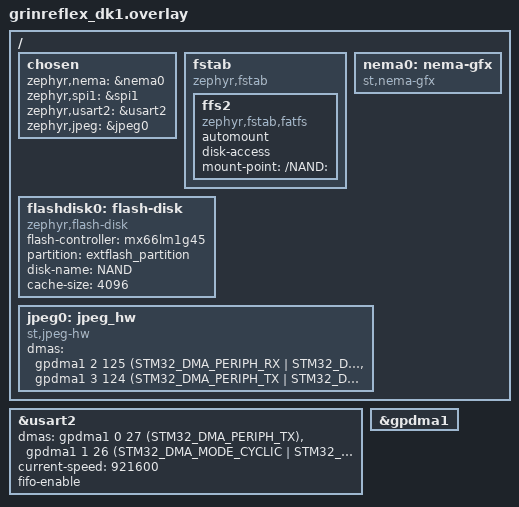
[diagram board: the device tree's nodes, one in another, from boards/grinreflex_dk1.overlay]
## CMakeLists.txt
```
#-------------------------------------------------------------------------------
# Zephyr Example Application
#
# Copyright (c) 2021 Nordic Semiconductor ASA
# SPDX-License-Identifier: Apache-2.0

cmake_minimum_required(VERSION 3.13.1)

set(EXTRA_CONF_FILE
    ${CMAKE_CURRENT_SOURCE_DIR}/lvgl.conf;
)

find_package(Zephyr REQUIRED HINTS $ENV{ZEPHYR_BASE})

project(app)

# TODO: below two lines are unclear
set(NO_THREADSAFE_STATICS $<TARGET_PROPERTY:compiler-cpp,no_threadsafe_statics>)
zephyr_compile_options($<$<COMPILE_LANGUAGE:CXX>:${NO_THREADSAFE_STATICS}>)

if (CONFIG_OPENCV_LIB)
    include(opencv.cmake)
endif()

if (CONFIG_NEMA)
    include(nema.cmake)
endif()

target_include_directories(app PRIVATE
    src
)

target_sources(app PRIVATE
    src/main.c
    src/gfx_utils.cpp
    src/video.cpp
)

if (CONFIG_BOARD_GRINREFLEX_DK1)
target_sources(app PRIVATE
    src/sample_usbd_init.c
    src/lvgl_fs_sample.c
    src/uart.cpp
    src/grinreflex.cpp
)
endif()

if (CONFIG_BOARD_GRINREFLEX_DK2)
target_sources(app PRIVATE
    src/grinreflex_v2.cpp
)
endif()
```

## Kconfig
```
# Copyright (c) 2021 Nordic Semiconductor ASA
# SPDX-License-Identifier: Apache-2.0
#
# This file is the application Kconfig entry point. All application Kconfig
# options can be defined here or included via other application Kconfig files.
# You can browse these options using the west targets menuconfig (terminal) or
# guiconfig (GUI).

#menu "Zephyr"
#source "Kconfig.zephyr"
#endmenu

module = grinreflex
module-str = grinreflex

source "subsys/logging/Kconfig.template.log_config"
source "Kconfig.zephyr"
rsource "Kconfig.sample_usbd"
rsource "Kconfig.sample_msc"
```

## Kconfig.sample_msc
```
menu "MSC sample options"

choice
	prompt "Storage and file system type used by the application"
	default APP_MSC_STORAGE_FLASH_FATFS
	help
	  Specify the type of storage and file system.

config APP_MSC_STORAGE_FLASH_FATFS
	bool "Use FLASH disk and FAT file system"
	imply DISK_DRIVERS
    imply DISK_ACCESS
	imply FILE_SYSTEM
	imply FAT_FILESYSTEM_ELM
    imply FILE_SYSTEM_MKFS
    imply FS_FATFS_FSTAB_AUTOMOUNT

endchoice

config MASS_STORAGE_DISK_NAME
	default "NAND" if DISK_DRIVER_FLASH

if DISK_DRIVER_FLASH

config FLASH_MAP
	default y

config FLASH_PAGE_LAYOUT
	default y

config FLASH_LOG_LEVEL
	default 3

endif # DISK_DRIVER_FLASH

endmenu
```

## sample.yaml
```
# This file is provided so that the application can be compiled using Twister,
# the Zephyr testing tool. In this file, multiple combinations can be specified,
# so that you can easily test all of them locally or in CI.
sample:
  description: Example application
  name: example-application 
common:
  build_only: true
  integration_platforms:
    - custom_plank
    - nucleo_f302r8
    - grinreflex-dk1

  modules:
    - lvgl
    - tflite-micro
```

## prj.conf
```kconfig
# Copyright (c) 2021 Nordic Semiconductor ASA
# SPDX-License-Identifier: Apache-2.0
#
# This is a Kconfig fragment which can be used to enable debug-related options
# in the application. See the README for more details.

CONFIG_CPP=y
CONFIG_STD_CPP20=y

CONFIG_MAIN_STACK_SIZE=65536

CONFIG_DISPLAY=y
CONFIG_DISPLAY_LOG_LEVEL_ERR=y

CONFIG_LOG=y
CONFIG_LOG_DEFAULT_LEVEL=3
CONFIG_SHELL=y

CONFIG_INPUT=y

CONFIG_LOG=y
CONFIG_LOG_MODE_MINIMAL=y
CONFIG_USB_DEVICE_INITIALIZE_AT_BOOT=n

CONFIG_REQUIRES_FULL_LIBC=y
CONFIG_GLIBCXX_LIBCPP=y

CONFIG_NEWLIB_LIBC=y
CONFIG_PICOLIBC=n

CONFIG_POSIX_API=y

CONFIG_ASSERT=y
CONFIG_STACK_SENTINEL=y
CONFIG_THREAD_STACK_INFO=y
CONFIG_INIT_STACKS=y           # fill stacks, helps detect overflow
CONFIG_LOG=y
CONFIG_LOG_MODE_DEFERRED=n     # immediate logs
CONFIG_DEBUG_OPTIMIZATIONS=y

CONFIG_COMMON_LIBC_MALLOC=y
CONFIG_HEAP_MEM_POOL_SIZE=49152
CONFIG_COMMON_LIBC_MALLOC_ARENA_SIZE=2228224
#CONFIG_COMMON_LIBC_MALLOC_ARENA_SIZE=1048576


#CONFIG_TFLITE_LIB=y
CONFIG_OPENCV_LIB=y
#CONFIG_QUIRC_LIB=y
CONFIG_NEMA=y

CONFIG_FPU=y
CONFIG_FP_SOFTABI=y

CONFIG_GPIO=y
#CONFIG_SPI=y
#CONFIG_SPI_LOG_LEVEL_DBG=y

CONFIG_DMA=y
CONFIG_SERIAL=y
CONFIG_UART_ASYNC_API=y
CONFIG_RING_BUFFER=y
#CONFIG_UART_LOG_LEVEL_DBG=y


CONFIG_UART_INTERRUPT_DRIVEN=y

CONFIG_STM32_JPEG=y

CONFIG_CPP_EXCEPTIONS=y
CONFIG_CPP_RTTI=y

#CONFIG_DISPLAY_LOG_LEVEL_DBG=y

CONFIG_DMA_LOG_LEVEL_INF=y
CONFIG_VIDEO_LOG_LEVEL_INF=y

CONFIG_STM32_JPEG_RGB_FORMAT=3
CONFIG_GRINREFLEX_JPEG_VIDEO=y
CONFIG_GRINREFLEX_JPEG_VIDEO_QUALITY=50
CONFIG_GRINREFLEX_VIDEO_WIDTH=320
CONFIG_GRINREFLEX_VIDEO_HEIGHT=240


CONFIG_HW_STACK_PROTECTION=y


# Make asserts print file:line and message
CONFIG_ASSERT=y
CONFIG_ASSERT_VERBOSE=y

# Ensure logs/printk come out before the crash
CONFIG_PRINTK=y
CONFIG_LOG=y
CONFIG_LOG_PRINTK=y
CONFIG_LOG_MODE_IMMEDIATE=y

# Better symbols for gdb
#CONFIG_DEBUG_INFO=y
# (Optional) minimal optimizations for nicer backtraces
CONFIG_NO_OPTIMIZATIONS=y

# Richer fault dump on ARM (registers, etc.)
CONFIG_FAULT_DUMP=2
```

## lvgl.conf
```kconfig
CONFIG_LV_Z_MEM_POOL_SIZE=16384
CONFIG_LV_Z_SHELL=n

CONFIG_LVGL=y
CONFIG_LV_USE_LOG=y
CONFIG_LV_USE_LABEL=y
CONFIG_LV_USE_ARC=y
CONFIG_LV_USE_IMAGE=y
#CONFIG_LV_USE_MONKEY=y
CONFIG_LV_FONT_MONTSERRAT_14=y
#CONFIG_LV_Z_POINTER_INPUT=y

CONFIG_LV_CACHE_DEF_SIZE=4096
CONFIG_LV_IMAGE_HEADER_CACHE_DEF_CNT=1
#CONFIG_LV_USE_TJPGD=y
#CONFIG_LV_USE_FS_MEMFS=y
#CONFIG_LV_USE_FS=y
CONFIG_LV_USE_BUILTIN_MALLOC=n

#CONFIG_LV_USE_PERF_MONITOR=y
#CONFIG_LV_USE_DROPDOWN=y
#CONFIG_LV_USE_SYSMON=y
```

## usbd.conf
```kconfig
CONFIG_USB_DEVICE_STACK_NEXT=y
CONFIG_USBD_MSC_CLASS=y
CONFIG_USBD_MSC_LUNS_PER_INSTANCE=3
CONFIG_USBD_LOG_LEVEL_WRN=y
CONFIG_UDC_DRIVER_LOG_LEVEL_WRN=y

CONFIG_SAMPLE_USBD_PID=0x0008
CONFIG_SAMPLE_USBD_PRODUCT="USBD MSC sample"
```

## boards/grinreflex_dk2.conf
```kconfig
CONFIG_FAT_FILESYSTEM_ELM=n
CONFIG_POSIX_FILE_SYSTEM=n
```

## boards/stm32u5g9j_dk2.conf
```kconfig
CONFIG_USB_DEVICE_STACK_NEXT=y
CONFIG_USBD_MSC_CLASS=y
CONFIG_USBD_MSC_LUNS_PER_INSTANCE=3
CONFIG_USBD_LOG_LEVEL_WRN=y
CONFIG_UDC_DRIVER_LOG_LEVEL_WRN=y

CONFIG_SAMPLE_USBD_PID=0x0008
CONFIG_SAMPLE_USBD_PRODUCT="USBD MSC sample"

CONFIG_FILE_SYSTEM_SHELL=y
```

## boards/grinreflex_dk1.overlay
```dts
/*
 * Copyright (c) 2024, Eve Redero
 *
 * SPDX-License-Identifier: Apache-2.0
 */

#include <zephyr/dt-bindings/input/input-event-codes.h>
#include <zephyr/dt-bindings/lvgl/lvgl.h>

/ {
	chosen: chosen {
		zephyr,nema = &nema0;
		zephyr,spi1 = &spi1;
		zephyr,usart2 = &usart2;
		zephyr,jpeg = &jpeg0;
	};

	fstab {
		compatible = "zephyr,fstab";

        ffs2: ffs2 {
			compatible = "zephyr,fstab,fatfs";
			automount;
			disk-access;
			mount-point = "/NAND:";
		};
	};

    flashdisk0: flash-disk {
        compatible = "zephyr,flash-disk";
        flash-controller = <&mx66lm1g45>;
        partition = <&extflash_partition>;
        disk-name = "NAND";
        cache-size = <4096>;
    };

	nema0: nema-gfx {
		compatible = "st,nema-gfx";
		status = "okay";
	};

	jpeg0: jpeg_hw {
		compatible = "st,jpeg-hw";
		dmas = <&gpdma1 2 125 (STM32_DMA_PERIPH_RX | STM32_DMA_PERIPH_32BITS | STM32_DMA_MEM_32BITS)
				&gpdma1 3 124 (STM32_DMA_PERIPH_TX | STM32_DMA_PERIPH_32BITS | STM32_DMA_MEM_32BITS)>;
		dma-names = "tx", "rx";
		status = "okay";
	};
};

&usart2 {
	dmas = <&gpdma1 0 27 (STM32_DMA_PERIPH_TX)
			&gpdma1 1 26 (STM32_DMA_MODE_CYCLIC | STM32_DMA_PERIPH_RX | STM32_DMA_MEM_8BITS)>;
	dma-names = "tx", "rx";
	current-speed = <921600>;
	fifo-enable;
};

&gpdma1 {
	status = "okay";
};
```

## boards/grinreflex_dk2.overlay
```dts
/*
 * Copyright (c) 2024, Eve Redero
 *
 * SPDX-License-Identifier: Apache-2.0
 */

#include <zephyr/dt-bindings/input/input-event-codes.h>
#include <zephyr/dt-bindings/lvgl/lvgl.h>

/ {
	chosen: chosen {
		zephyr,nema = &nema0;
		zephyr,spi1 = &spi1;
		zephyr,jpeg = &jpeg0;
	};

	nema0: nema-gfx {
		compatible = "st,nema-gfx";
		status = "okay";
	};

	jpeg0: jpeg_hw {
		compatible = "st,jpeg-hw";
		dmas = <&gpdma1 2 125 (STM32_DMA_PERIPH_RX | STM32_DMA_PERIPH_32BITS | STM32_DMA_MEM_32BITS)
				&gpdma1 3 124 (STM32_DMA_PERIPH_TX | STM32_DMA_PERIPH_32BITS | STM32_DMA_MEM_32BITS)>;
		dma-names = "tx", "rx";
		status = "okay";
	};
};

&gpdma1 {
	status = "okay";
};

&dcmi {
	jpeg-dev = <&jpeg0>;
};
```

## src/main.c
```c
/*
 * Copyright (c) 2024 Charles Dias <charlesdias.cd@outlook.com>
 *
 * SPDX-License-Identifier: Apache-2.0
 */

#include <zephyr/kernel.h>
#include <zephyr/device.h>
#include <zephyr/drivers/display.h>
#include <zephyr/drivers/video.h>
#include <zephyr/drivers/video-controls.h>
#include <zephyr/logging/log.h>
#include <lvgl.h>

#define CONFIG_VIDEO_WIDTH 160
#define CONFIG_VIDEO_HEIGHT 120

#include "grinreflex.h"

LOG_MODULE_REGISTER(main, CONFIG_LOG_DEFAULT_LEVEL);

#if !DT_HAS_CHOSEN(zephyr_camera)
#error No camera chosen in devicetree. Missing "--shield" or "--snippet video-sw-generator" flag?
#endif

#if !DT_HAS_CHOSEN(zephyr_display)
#error No display chosen in devicetree. Missing "--shield" flag?
#endif

int main(void)
{
	init();

	while (1)
	{
		loop();
	}
}
```

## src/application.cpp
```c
#include <iostream>

#include "lvgl.h"

#include "gfx_utils.hpp"
#if defined(CONFIG_OPENCV_LIB)
#include "opencv_utils.hpp"
#endif

#include "uart.hpp"
#include <app/drivers/jpeg.h>

#include "application.h"

#define JPEG_DEVICE_NODE DT_CHOSEN(zephyr_jpeg)

#define NAND_PATH(_path) ("/NAND:" _path)

#if defined(CONFIG_OPENCV_LIB)
static cv::CascadeClassifier faceCascade;
#endif

#define UART_RING_BUF_SIZE 8192
static uint8_t uart_ring_buf[UART_RING_BUF_SIZE];

static lv_obj_t *canvas;
static lv_obj_t *jpeg_img;

UartEx uartEx = UartEx(uart_ring_buf, sizeof(uart_ring_buf));

const struct device *jpeg_dev = DEVICE_DT_GET(JPEG_DEVICE_NODE);

int init() {

#if defined(CONFIG_OPENCV_LIB)
  const char *faceCascadePath = NAND_PATH("/alt.xml");

  cv::setNumThreads(1);

  uint32_t start_ms = k_uptime_get_32();

  if (!faceCascade.load(faceCascadePath)) {
    std::cerr << "Cannot load cascade: " << faceCascadePath << "\n";
    return -3;
  }

  uint32_t end_ms = k_uptime_get_32();
  uint32_t elapsed = end_ms - start_ms;

  std::cout << "faceCascade.load : " << elapsed << std::endl;

  canvas = lv_canvas_create(lv_screen_active());
  lv_canvas_fill_bg(canvas, lv_color_hex3(0xccc), LV_OPA_COVER);
  lv_obj_center(canvas);

  jpeg_img = lv_img_create(lv_screen_active());

  uartEx.init();
  uartEx.trigger();

  if (!device_is_ready(jpeg_dev)) {
    printf("%s JPEG device not ready", jpeg_dev->name);
    return -ENODEV;
  }
#endif

  return 0;
}

#define TMP_BUF_WIDTH 400
#define TMP_BUF_HEIGHT 400

static uint8_t tmp_buf[TMP_BUF_WIDTH * TMP_BUF_HEIGHT];

int loop() {
#if defined(CONFIG_OPENCV_LIB)
  uint32_t jpeg_buf_len = uartEx.tryReadHeader();

  if (0 == jpeg_buf_len) {
    return 0;
  }

  // memset(tmp_buf, 0, sizeof(tmp_buf));

  static uint8_t uart_buf[8192];
  static uint8_t yuyv_buf[80 * 80 * 3];
  static uint8_t rgb_buf[80 * 80 * 3];
  struct jpeg_out_prop jpeg_prop;

  jpeg_buf_len = uartEx.tryRead(uart_buf, jpeg_buf_len);

  uartEx.trigger();

  jpeg_buf_len = ROUND_UP(jpeg_buf_len, 4);

  jpeg_hw_decode(jpeg_dev, uart_buf, jpeg_buf_len, yuyv_buf);

  jpeg_hw_poll(jpeg_dev, 0, &jpeg_prop);

  printf("JPEG done w = %d, h = %d, color = %d chroma = %d\n", jpeg_prop.width,
         jpeg_prop.height, jpeg_prop.color_space, jpeg_prop.chroma);

  jpeg_color_convert_helper(jpeg_dev, &jpeg_prop, yuyv_buf, rgb_buf);

  // memset(rgb_buf, 0xff, sizeof(rgb_buf));
  uint32_t rgb_size = 80 * 80 * 3;

  cv::Mat mat_rgb(jpeg_prop.height, jpeg_prop.width, CV_8UC3, rgb_buf);
  cv::Mat mat_gray;

  cv::cvtColor(mat_rgb, mat_gray, cv::COLOR_RGB2GRAY);

  const cv::Size minSize(20, 20);
  const cv::Size maxSize(mat_gray.cols, mat_gray.rows);
  const double scaleFactor = 1.3;
  const int minNeighbors = 3;
  const int flags = 0;

  std::vector<cv::Rect> faces;

  uint32_t start_ms = k_uptime_get_32();

  faceCascade.detectMultiScale(mat_gray, faces, scaleFactor, minNeighbors,
                               flags, minSize, maxSize);

  uint32_t end_ms = k_uptime_get_32();
  uint32_t elapsed = end_ms - start_ms;

  printf("detectMultiScale : %d ms\n", elapsed);

  for (const auto &r : faces) {
    cv::rectangle(mat_gray, r, cv::Scalar(255, 255, 255), 2, cv::LINE_8);
    std::cout << "detectMultiScale : " << elapsed << std::endl;
    printf("faces = %d, %d %d\n", faces.size(), mat_gray.cols, mat_gray.rows);
  }

  static Gfx::GfxBuffer src;
  static Gfx::GfxBuffer dst;

  src.buf = mat_gray.data;
  src.width = mat_gray.cols;
  src.height = mat_gray.rows;
  src.stride = mat_gray.cols;
  src.cf = LV_COLOR_FORMAT_L8;
  src.size = mat_gray.rows * mat_gray.cols;

  dst.buf = tmp_buf;
  dst.width = TMP_BUF_WIDTH;
  dst.height = TMP_BUF_HEIGHT;
  dst.stride = TMP_BUF_WIDTH;
  dst.size = sizeof(tmp_buf);
  dst.cf = LV_COLOR_FORMAT_L8;

  Gfx::fit(canvas, src, dst);
#endif
  return 0;
}

/////////////////// Examples /////////////////////////

#if 0

TFLite:

#define IMG_WIDTH 96
#define IMG_HEIGHT 96
#define IMG_BPP 3
#define IMG_SIZE (IMG_WIDTH * IMG_HEIGHT * IMG_BPP)

  static uint8_t img_buf[IMG_SIZE];

  static uint8_t edges_buf[IMG_SIZE / IMG_BPP];

  if (lvgl_fs_load_raw("/NAND:/test.bin", img_buf, IMG_SIZE)) {

    static lv_img_dsc_t img_dsc;
    img_dsc.header.w = IMG_WIDTH;
    img_dsc.header.h = IMG_HEIGHT;
    img_dsc.header.cf = LV_COLOR_FORMAT_A8; //
    img_dsc.data_size = IMG_SIZE / IMG_BPP;
    img_dsc.data = edges_buf;

    lv_obj_t *img = lv_img_create(lv_screen_active());

#if defined(CONFIG_TFLITE_LIB)
    tflm_init();
    inference_task(img_buf);
#endif

    lv_img_set_src(img, &img_dsc);
    lv_obj_center(img);
  }

Edges

#define IMG_WIDTH 320
#define IMG_HEIGHT 240
#define IMG_BPP 3
#define IMG_SIZE (IMG_WIDTH * IMG_HEIGHT * IMG_BPP)

	static uint8_t edges_buf[IMG_SIZE/IMG_BPP];

	uint32_t start_ms = k_uptime_get_32();
	//edge_detect(image_data(), edges_buf, IMG_WIDTH, IMG_HEIGHT, 50.0, 150.0);

	int width, height;
	if (0 == edge_demo("/NAND:/sample2.png", edges_buf, &width, &height, 50.0, 150.0))
	{

		uint32_t end_ms = k_uptime_get_32();
		uint32_t elapsed = end_ms - start_ms;

		printf("Routine took %u ms\n", elapsed);

		static lv_img_dsc_t img_dsc;
		img_dsc.header.w = IMG_WIDTH;
		img_dsc.header.h = IMG_HEIGHT;
		img_dsc.header.cf = LV_COLOR_FORMAT_A8; //
		img_dsc.data_size = IMG_SIZE/IMG_BPP;
		img_dsc.data = edges_buf;

		lv_obj_t *img = lv_img_create(lv_screen_active());

		lv_img_set_src(img, &img_dsc);
		lv_obj_center(img);
	}

void fs_example() {
  /* You can get direct mount point to automounted node too */
  struct fs_mount_t *mp = &FS_FSTAB_ENTRY(AUTOMOUNT_NODE);
  struct fs_dir_t dir;
  struct fs_statvfs sbuf;
  int rc;

  fs_dir_t_init(&dir);
  /* Allow log messages to flush to avoid interleaved output */
  k_sleep(K_MSEC(50));

  printk("Mount %s\n", mp->mnt_point);

  rc = fs_statvfs(mp->mnt_point, &sbuf);
  if (rc < 0) {
    printk("FAIL: statvfs: %d\n", rc);
    return;
  }

  printk("%s: bsize = %lu ; frsize = %lu ;"
         " blocks = %lu ; bfree = %lu\n",
         mp->mnt_point, sbuf.f_bsize, sbuf.f_frsize, sbuf.f_blocks,
         sbuf.f_bfree);

  rc = fs_opendir(&dir, mp->mnt_point);
  printk("%s opendir: %d\n", mp->mnt_point, rc);

  if (rc < 0) {
    LOG_ERR("Failed to open directory");
  }

  while (rc >= 0) {
    struct fs_dirent ent = {0};

    rc = fs_readdir(&dir, &ent);
    if (rc < 0) {
      LOG_ERR("Failed to read directory entries");
      break;
    }
    if (ent.name[0] == 0) {
      printk("End of files\n");
      break;
    }
    printk("  %c %u %s\n", (ent.type == FS_DIR_ENTRY_FILE) ? 'F' : 'D',
           ent.size, ent.name);
  }

  (void)fs_closedir(&dir);

  return;
}

#endif
```

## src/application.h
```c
#ifndef APPLICATION_H
#define APPLICATION_H

#include "stddef.h"
#include "stdint.h"

#ifdef __cplusplus
extern "C" {
#endif

int init();

int loop();

#ifdef __cplusplus
}
#endif

#endif /* APPLICATION_H */
```

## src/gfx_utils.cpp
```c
#include "gfx_utils.hpp"

namespace Gfx {

void fit(lv_obj_t *canvas, const GfxBuffer &src, const GfxBuffer &dst, bool flip_y) {

  lv_image_dsc_t src_img = {
      .header =
          {
              .magic = LV_IMAGE_HEADER_MAGIC,
              .cf = src.cf,
              .w = src.width,
              .h = src.height,
              .stride = src.stride,
          },
      .data_size = src.size,
      .data = src.buf,
  };

  lv_canvas_set_buffer(canvas, dst.buf, dst.width, dst.height,
                       static_cast<lv_color_format_t>(dst.cf));

  lv_layer_t layer{};
  lv_canvas_init_layer(canvas, &layer);
  lv_draw_image_dsc_t img_dsc;
  lv_draw_image_dsc_init(&img_dsc);

  img_dsc.src = &src_img;

  img_dsc.scale_x = (LV_SCALE_NONE * (int32_t)(dst.width)) / src.width;
  img_dsc.scale_y = (LV_SCALE_NONE * (int32_t)(dst.height)) / src.height;

  if (flip_y) {
    img_dsc.rotation = 1800;
    img_dsc.pivot.x = src.width  / 2;
    img_dsc.pivot.y = src.height / 2;
  }

  lv_area_t coords_img = {0, 0, src.width - 1, src.height - 1};

  lv_draw_image(&layer, &img_dsc, &coords_img);

  lv_canvas_finish_layer(canvas, &layer);
}

} // namespace Gfx
```

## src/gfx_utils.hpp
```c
#pragma once

#include "stddef.h"
#include "stdint.h"

#include <lvgl.h>

namespace Gfx {

struct GfxRect {
  uint32_t x, y;
  uint32_t width, height;
};

struct GfxBuffer {
  uint8_t *buf;
  uint32_t width, height, stride;
  size_t size;
  uint32_t cf;
};

/**
 * @brief Fit source buffer onto destination
 *
 */
void fit(lv_obj_t *canvas, const GfxBuffer &src, const GfxBuffer &dst, bool flip_y = false);

} // namespace Gfx
```

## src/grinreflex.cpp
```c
#include <iostream>
#include <vector>

#if defined(CONFIG_OPENCV_LIB)
#include "opencv2/opencv.hpp"
#endif 

#include <lvgl.h>
#include <lvgl_input_device.h>
#include <stdio.h>
#include <string.h>
#include <zephyr/device.h>
#include <zephyr/devicetree.h>
#include <zephyr/drivers/display.h>
#include <zephyr/drivers/gpio.h>
#include <zephyr/kernel.h>

#include <stdio.h>
#include <zephyr/fs/fs.h>

#include <zephyr/usb/class/usbd_msc.h>
#include <zephyr/usb/usb_device.h>
#include <zephyr/usb/usbd.h>
#include <sample_usbd.h>

#include <lvgl_fs.h>
#include <sample_usbd.h>

#define LOG_LEVEL CONFIG_LOG_DEFAULT_LEVEL
#include <zephyr/logging/log.h>
LOG_MODULE_REGISTER(grinreflex_app);

#include "grinreflex.h"
#include "video.hpp"
#include "gfx_utils.hpp"

#include <app/drivers/jpeg.h>

#if defined(CONFIG_OPENCV_LIB)
#include "opencv_utils.hpp"
#endif

#if defined(CONFIG_QUIRC_LIB)
#include "quirc.h"
#endif

#if defined(CONFIG_TFLITE_LIB)
#include "app/lib/tflm.h"
#endif

#if defined(CONFIG_TFLITE_LIB) && defined(CONFIG_OPENCV_LIB)
#error "Can't use both CONFIG_TFLITE_LIB and CONFIG_OPENCV_LIB at the same time"
#endif

#define NAND_PATH(_path) ("/NAND:" _path)

#define AUTOMOUNT_NODE DT_NODELABEL(ffs2)
FS_FSTAB_DECLARE_ENTRY(AUTOMOUNT_NODE);

static struct usbd_context *sample_usbd;
static lv_obj_t *vid_canvas;

#if defined(CONFIG_GRINREFLEX_JPEG_VIDEO)

//static uint8_t jpeg_frame_buffer[CONFIG_GRINREFLEX_VIDEO_WIDTH * CONFIG_GRINREFLEX_VIDEO_HEIGHT * LV_COLOR_FORMAT_GET_SIZE(LV_COLOR_FORMAT_RGB888)];
static uint8_t rgb_frame_buffer[CONFIG_GRINREFLEX_VIDEO_WIDTH * CONFIG_GRINREFLEX_VIDEO_HEIGHT * LV_COLOR_FORMAT_GET_SIZE(JPEG_COLOR_FORMAT)];

#endif

USBD_DEFINE_MSC_LUN(flash, "NAND", "Zephyr", "FlashDisk", "0.00");

static const struct device *video_dev = DEVICE_DT_GET(DT_CHOSEN(zephyr_camera));
static const struct device *display_dev = DEVICE_DT_GET(DT_CHOSEN(zephyr_display));
const struct device *jpeg_dev = DEVICE_DT_GET(DT_CHOSEN(zephyr_jpeg));

#if defined(CONFIG_OPENCV_LIB)
static lv_obj_t *RedGreenDot;
static lv_obj_t *FaceRect;
static cv::CascadeClassifier faceCascade;
static cv::QRCodeDetector qrCodeDetector;

#define OPECV_SHOWCASE OCV_SC_FACE_DETECT

#endif /* defined(CONFIG_OPENCV_LIB) */

static uint8_t gray_frame_buffer[GRAY_FRAME_WIDTH * GRAY_FRAME_HEIGHT * LV_COLOR_FORMAT_GET_SIZE(LV_COLOR_FORMAT_L8)];

#if defined(CONFIG_TFLITE_LIB)
#define TFLM_INFERENCE_WIDTH 96
#define TFLM_INFERENCE_HEIGHT 96

static uint8_t tflm_rgb_frame_buffer[TFLM_INFERENCE_WIDTH * TFLM_INFERENCE_HEIGHT * LV_COLOR_FORMAT_GET_SIZE(LV_COLOR_FORMAT_RGB888)];
#endif

static int enable_usb_device_next(void) {
  int err;

  sample_usbd = sample_usbd_init_device(NULL);
  if (sample_usbd == NULL) {
    LOG_ERR("Failed to initialize USB device");
    return -ENODEV;
  }

  err = usbd_enable(sample_usbd);
  if (err) {
    LOG_ERR("Failed to enable device support");
    return err;
  }

  LOG_DBG("USB device support enabled");

  return 0;
}

static lv_img_dsc_t video_img;
static lv_obj_t *screen;

int init()
{
	if (!device_is_ready(display_dev)) {
		LOG_ERR("Device not ready, aborting test");
		return -ENODEV;
	}

    if (!device_is_ready(jpeg_dev)) {
        printf("%s JPEG device not ready", jpeg_dev->name);
        return -ENODEV;
    }

	if (0 && enable_usb_device_next() != 0) {
		LOG_ERR("Failed to enable USB");
        return -ENODEV;
    }

#if defined(CONFIG_TFLITE_LIB)
    tflm_init();
#endif

#if defined(CONFIG_OPENCV_LIB)

    cv::setNumThreads(1);
    cv::setUseOptimized(false);

#if (OPECV_SHOWCASE == OCV_SC_FACE_DETECT)
    const char *faceCascadePath = NAND_PATH("/cascface.xml");
    if (false == loadCascade(faceCascade, faceCascadePath)) {
        return -3;
    }
#endif
#endif

    Video::setup();

    vid_canvas = lv_canvas_create(lv_screen_active());
    lv_canvas_fill_bg(vid_canvas, lv_color_hex3(0xccc), LV_OPA_COVER);
    lv_obj_center(vid_canvas);

    display_blanking_off(display_dev);

    video_img.header.w = CONFIG_GRINREFLEX_VIDEO_WIDTH;
	video_img.header.h = CONFIG_GRINREFLEX_VIDEO_HEIGHT;
#if defined(CONFIG_GRINREFLEX_JPEG_VIDEO)
	video_img.data_size = CONFIG_GRINREFLEX_VIDEO_WIDTH * CONFIG_GRINREFLEX_VIDEO_HEIGHT * LV_COLOR_FORMAT_GET_SIZE(JPEG_COLOR_FORMAT);
	video_img.header.cf = JPEG_COLOR_FORMAT;
#else
	video_img.data_size = CONFIG_GRINREFLEX_VIDEO_WIDTH * CONFIG_GRINREFLEX_VIDEO_HEIGHT * LV_COLOR_FORMAT_GET_SIZE(LV_COLOR_FORMAT_NATIVE);
	video_img.header.cf = LV_COLOR_FORMAT_NATIVE;
#endif
    screen = lv_img_create(lv_scr_act());

#if defined(CONFIG_OPENCV_LIB)
    RedGreenDot = lv_obj_create(lv_scr_act());
    lv_obj_set_size(RedGreenDot, 30, 30);                    // dot size
    lv_obj_set_style_radius(RedGreenDot, LV_RADIUS_CIRCLE, 0); // make it round
    lv_obj_set_style_border_width(RedGreenDot, 0, 0);
    lv_obj_set_style_bg_opa(RedGreenDot, LV_OPA_COVER, 0);
    lv_obj_clear_flag(RedGreenDot, LV_OBJ_FLAG_SCROLLABLE);
    lv_obj_align(RedGreenDot, LV_ALIGN_LEFT_MID, 4, 0);      // 4px from left
    lv_obj_move_foreground(RedGreenDot);                     // keep it on top

    FaceRect = lv_obj_create(lv_scr_act());
    lv_obj_set_pos(FaceRect, 0, 0);
    lv_obj_set_size(FaceRect, 1, 1);

    // Unfilled, just a thick border
    lv_obj_set_style_bg_opa(FaceRect, LV_OPA_TRANSP, LV_PART_MAIN);
    lv_obj_set_style_border_width(FaceRect, 4, LV_PART_MAIN);
    lv_obj_set_style_border_opa(FaceRect, LV_OPA_COVER, LV_PART_MAIN);
    lv_obj_set_style_border_color(FaceRect, lv_palette_main(LV_PALETTE_GREEN), LV_PART_MAIN);
    lv_obj_set_style_radius(FaceRect, 0, LV_PART_MAIN);      // 0 = sharp corners
    lv_obj_set_style_pad_all(FaceRect, 0, LV_PART_MAIN);
    lv_obj_set_style_outline_opa(FaceRect, LV_OPA_TRANSP, LV_PART_MAIN); // no focus outline
    lv_obj_set_style_shadow_opa(FaceRect, LV_OPA_TRANSP, LV_PART_MAIN);  // no shadow
    lv_obj_move_foreground(FaceRect);
    lv_obj_add_flag(FaceRect, LV_OBJ_FLAG_HIDDEN);

#endif
    return 0;
}

int loop()
{
    struct video_buffer vbuf{};
    struct video_buffer *vbuf_ptr = &vbuf;
    struct jpeg_out_prop jpeg_prop;

    vbuf_ptr->type = VIDEO_BUF_TYPE_OUTPUT;
    
    int err = video_dequeue(video_dev, &vbuf_ptr, K_FOREVER);
    if (err) {
        LOG_ERR("Unable to dequeue video buf");
        return 0;
    }

#if defined(CONFIG_GRINREFLEX_JPEG_VIDEO)
    //jpeg_hw_decode(jpeg_dev, (uint8_t *)vbuf_ptr->buffer, vbuf_ptr->bytesused, jpeg_frame_buffer);

    jpeg_hw_poll(jpeg_dev, 0, &jpeg_prop);

    //printf("JPEG done w = %d, h = %d, color = %d chroma = %d\n", jpeg_prop.width,
    //        jpeg_prop.height, jpeg_prop.color_space, jpeg_prop.chroma);

    jpeg_color_convert_helper(jpeg_dev, &jpeg_prop, vbuf_ptr->buffer, rgb_frame_buffer);

#else
    video_img.data = (uint8_t *)vbuf_ptr->buffer;
    lv_img_set_src(screen, &video_img);
	lv_obj_align(screen, LV_ALIGN_BOTTOM_LEFT, 0, 0);
    lv_task_handler();
#endif

#if !defined(CONFIG_OPENCV_LIB) && !defined(CONFIG_TFLITE_LIB)
    Gfx::GfxBuffer src{};
    Gfx::GfxBuffer dst{};

    src.buf = rgb_frame_buffer;
    src.width = CONFIG_GRINREFLEX_VIDEO_WIDTH;
    src.height = CONFIG_GRINREFLEX_VIDEO_HEIGHT;
    src.stride = CONFIG_GRINREFLEX_VIDEO_WIDTH * LV_COLOR_FORMAT_GET_SIZE(JPEG_COLOR_FORMAT);
    src.cf = JPEG_COLOR_FORMAT;
    src.size = CONFIG_GRINREFLEX_VIDEO_HEIGHT * CONFIG_GRINREFLEX_VIDEO_WIDTH * LV_COLOR_FORMAT_GET_SIZE(JPEG_COLOR_FORMAT);

    dst.buf = gray_frame_buffer;
    dst.width = GRAY_FRAME_WIDTH;
    dst.height = GRAY_FRAME_HEIGHT;
    dst.stride = GRAY_FRAME_WIDTH * LV_COLOR_FORMAT_GET_SIZE(LV_COLOR_FORMAT_L8);
    dst.cf = LV_COLOR_FORMAT_L8;
    dst.size = sizeof(gray_frame_buffer);

    Gfx::fit(vid_canvas, src, dst);
    lv_task_handler();

    err = video_enqueue(video_dev, vbuf_ptr);
    if (err) {
        LOG_ERR("Unable to requeue video buf");
        return 0;
    }
#endif

#if defined(CONFIG_TFLITE_LIB)

    Gfx::GfxBuffer src{};
    Gfx::GfxBuffer dst{};

    src.buf = rgb_frame_buffer;
    src.width = CONFIG_GRINREFLEX_VIDEO_WIDTH;
    src.height = CONFIG_GRINREFLEX_VIDEO_HEIGHT;
    src.stride = CONFIG_GRINREFLEX_VIDEO_WIDTH * LV_COLOR_FORMAT_GET_SIZE(JPEG_COLOR_FORMAT);
    src.cf = JPEG_COLOR_FORMAT;
    src.size = sizeof(rgb_frame_buffer);

    dst.buf = tflm_rgb_frame_buffer;
    dst.width = TFLM_INFERENCE_WIDTH;
    dst.height = TFLM_INFERENCE_HEIGHT;
    dst.stride = TFLM_INFERENCE_WIDTH * LV_COLOR_FORMAT_GET_SIZE(LV_COLOR_FORMAT_RGB888);
    dst.cf = LV_COLOR_FORMAT_RGB888;
    dst.size = sizeof(tflm_rgb_frame_buffer);

    Gfx::fit(vid_canvas, src, dst);
    lv_task_handler();

    err = video_enqueue(video_dev, vbuf_ptr);
    if (err) {
        LOG_ERR("Unable to requeue video buf");
        return 0;
    }

    inference_task(tflm_rgb_frame_buffer);
#endif /* defined(CONFIG_TFLITE_LIB) */

#if defined(CONFIG_OPENCV_LIB)
    Gfx::GfxBuffer src{};
    Gfx::GfxBuffer dst{};

    src.buf = rgb_frame_buffer;
    src.width = CONFIG_GRINREFLEX_VIDEO_WIDTH;
    src.height = CONFIG_GRINREFLEX_VIDEO_HEIGHT;
    src.stride = CONFIG_GRINREFLEX_VIDEO_WIDTH * LV_COLOR_FORMAT_GET_SIZE(JPEG_COLOR_FORMAT);
    src.cf = JPEG_COLOR_FORMAT;
    src.size = sizeof(rgb_frame_buffer);

    dst.buf = gray_frame_buffer;
    dst.width = GRAY_FRAME_WIDTH;
    dst.height = GRAY_FRAME_HEIGHT;
    dst.stride = GRAY_FRAME_WIDTH * LV_COLOR_FORMAT_GET_SIZE(LV_COLOR_FORMAT_L8);
    dst.cf = LV_COLOR_FORMAT_L8;
    dst.size = sizeof(gray_frame_buffer);

    Gfx::fit(vid_canvas, src, dst);
    lv_task_handler();

    err = video_enqueue(video_dev, vbuf_ptr);
    if (err) {
        LOG_ERR("Unable to requeue video buf");
        return 0;
    }

#if (OPECV_SHOWCASE == OCV_SC_FACE_DETECT)
    cv::Mat mat_gray(GRAY_FRAME_WIDTH, GRAY_FRAME_HEIGHT, CV_8UC1, gray_frame_buffer);

    std::vector<cv::Rect> faces;

    bool facesFound = detectFaces(faceCascade, mat_gray, faces);

    lv_color_t c = facesFound ? lv_palette_main(LV_PALETTE_GREEN)
                                : lv_palette_main(LV_PALETTE_RED);
    lv_obj_set_style_bg_color(RedGreenDot, c, 0);

    if (facesFound) lv_obj_remove_flag(FaceRect, LV_OBJ_FLAG_HIDDEN);
    else         lv_obj_add_flag(FaceRect, LV_OBJ_FLAG_HIDDEN);

    for (const auto &r : faces) {
        //cv::rectangle(mat_gray, r, cv::Scalar(255, 255, 255), 2, cv::LINE_8);
        printf("faces = %d, %d %d\n", faces.size(), r.x, r.y);

        lv_obj_align_to(FaceRect, vid_canvas, LV_ALIGN_TOP_LEFT, r.x, r.y);
        lv_obj_set_size(FaceRect, r.width, r.height);
    }
#elif (OPECV_SHOWCASE == OCV_SC_QRCODE)
    cv::Mat gray(GRAY_FRAME_WIDTH, GRAY_FRAME_HEIGHT, CV_8UC1, gray_frame_buffer);
    cv::Mat bgr(jpeg_prop.width, jpeg_prop.height, CV_8UC3, rgb_frame_buffer);
    
    try {
        cv::Mat bin = cv_preprocessForQR(gray);

        cv::Mat ptsSingle;
        uint32_t start_ms = k_uptime_get_32();

        std::string text = qrCodeDetector.detectAndDecode(bin, ptsSingle);
        uint32_t end_ms = k_uptime_get_32();
        uint32_t elapsed = end_ms - start_ms;
        
        if (!text.empty()) {
            std::cout << "Decoded text : " << text << std::endl;
            std::cout << "Time taken " << elapsed << " ms" << std::endl;
        }
    } catch (cv::Exception e) {
        std::cout << "Caught exception " << e.what() << std::endl;
    }
#endif

#if defined(CONFIG_QUIRC_LIB)
#if (OPECV_SHOWCASE == OCV_SC_QRCODE_QUIRC)
    cv::Mat gray(GRAY_FRAME_WIDTH, GRAY_FRAME_HEIGHT, CV_8UC1, gray_frame_buffer);
    struct quirc *qr;

    qr = quirc_new();
    if (!qr) {
        std::cout << "quirc: Failed to allocate memory" << std::endl;
        return -ENOMEM;
    }

    if (quirc_resize(qr, GRAY_FRAME_WIDTH, GRAY_FRAME_HEIGHT) < 0) {
        std::cout << "quirc: Failed to allocate video memory" << std::endl;
        return -ENOMEM;
    }

    uint8_t *image;
    int w, h;
    bool qrDecodedOk = false;

    uint32_t start_ms = k_uptime_get_32();

    image = quirc_begin(qr, &w, &h);

    std::memcpy(image, gray.data, (size_t)(w * h));
    quirc_end(qr);

    int num_codes;
    int i;

    num_codes = quirc_count(qr);
    for (i = 0; i < num_codes; i++) {
        struct quirc_code code;
        struct quirc_data data;
        quirc_decode_error_t err;

        quirc_extract(qr, i, &code);

        /* Decoding stage */
        err = quirc_decode(&code, &data);
        if (err) {
            printf("DECODE FAILED: %s\n", quirc_strerror(err));
            return -EPERM;
        } else {
            qrDecodedOk = true;
            printf("Data: %s\n", data.payload);
        }
    }

    quirc_destroy(qr);

    uint32_t end_ms = k_uptime_get_32();
    uint32_t elapsed = end_ms - start_ms;

    if (qrDecodedOk) {
        std::cout << "Time Taken : " << elapsed << " ms" << std::endl; 
    }

#endif /* (OPECV_SHOWCASE == OCV_SC_QRCODE_QUIRC)  */
#endif /* defined(CONFIG_QUIRC_LIB) */
#endif /* defined(CONFIG_OPENCV_LIB) */
    return 0;
}
```

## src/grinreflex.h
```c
#ifndef GRINREFLEX_APPLICATION_H
#define GRINREFLEX_APPLICATION_H

#include "stddef.h"
#include "stdint.h"

#ifdef __cplusplus
extern "C" {
#endif

#if defined(CONFIG_GRINREFLEX_JPEG_VIDEO)

#if defined(CONFIG_STM32_JPEG_RGB_FORMAT)
#if CONFIG_STM32_JPEG_RGB_FORMAT == 0
#define JPEG_COLOR_FORMAT LV_COLOR_FORMAT_ARGB8888
#elif CONFIG_STM32_JPEG_RGB_FORMAT == 1
#define JPEG_COLOR_FORMAT LV_COLOR_FORMAT_RGB888
#elif CONFIG_STM32_JPEG_RGB_FORMAT == 2
#define JPEG_COLOR_FORMAT LV_COLOR_FORMAT_RGB565
#elif CONFIG_STM32_JPEG_RGB_FORMAT == 3
#define JPEG_COLOR_FORMAT LV_COLOR_FORMAT_L8
#else
#error "CONFIG_STM32_JPEG_RGB_FORMAT is not supported"
#endif

#else
#define JPEG_COLOR_FORMAT LV_COLOR_FORMAT_RGB888
#endif /* defined(CONFIG_STM32_JPEG_RGB_FORMAT) */

#endif /* defined(CONFIG_GRINREFLEX_JPEG_VIDEO) */

#define GRAY_FRAME_WIDTH 80
#define GRAY_FRAME_HEIGHT 80


int init();

int loop();

#ifdef __cplusplus
}
#endif

#endif /* GRINREFLEX_APPLICATION_H */
```

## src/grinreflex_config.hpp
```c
#pragma once


#if !defined(CONFIG_GRINREFLEX_JPEG_VIDEO)
#error "Not supported yet"
#endif

#if defined(CONFIG_STM32_JPEG_RGB_FORMAT)
#if CONFIG_STM32_JPEG_RGB_FORMAT == 0
#define FULL_FRAME_COLOR_FORMAT LV_COLOR_FORMAT_ARGB8888
#elif CONFIG_STM32_JPEG_RGB_FORMAT == 1
#define FULL_FRAME_COLOR_FORMAT LV_COLOR_FORMAT_RGB888
#elif CONFIG_STM32_JPEG_RGB_FORMAT == 2
#define FULL_FRAME_COLOR_FORMAT LV_COLOR_FORMAT_RGB565
#elif CONFIG_STM32_JPEG_RGB_FORMAT == 3
#define FULL_FRAME_COLOR_FORMAT LV_COLOR_FORMAT_L8
#else
#error "CONFIG_STM32_JPEG_RGB_FORMAT is not supported"
#endif

#else
#define FULL_FRAME_COLOR_FORMAT LV_COLOR_FORMAT_RGB888
#endif /* defined(CONFIG_STM32_JPEG_RGB_FORMAT) */

#define FULL_FRAME_WIDTH CONFIG_GRINREFLEX_VIDEO_WIDTH
#define FULL_FRAME_HEIGHT CONFIG_GRINREFLEX_VIDEO_HEIGHT

#define ROI_FRAME_WIDTH 320
#define ROI_FRAME_HEIGHT 240

#define THUMBNAIL_FRAME_WIDTH 80
#define THUMBNAIL_FRAME_HEIGHT 80

//#define FULL_FRAME_FLIP_Y (1)
```

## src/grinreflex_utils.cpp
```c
#include "grinreflex_config.hpp"
#include "gfx_utils.hpp"

#include "grinreflex_utils.hpp"

lv_obj_t *allocLvROIRect(lv_obj_t *parent, uint32_t borderWidth) {
    lv_obj_t *rect = lv_obj_create(parent);
    lv_obj_set_pos(rect, 0, 0);
    lv_obj_set_size(rect, 1, 1);

    // Unfilled, just a thick border
    lv_obj_set_style_bg_opa(rect, LV_OPA_TRANSP, LV_PART_MAIN);
    lv_obj_set_style_border_width(rect, borderWidth, LV_PART_MAIN);
    lv_obj_set_style_border_opa(rect, LV_OPA_COVER, LV_PART_MAIN);
    lv_obj_set_style_border_color(rect, lv_palette_main(LV_PALETTE_GREEN), LV_PART_MAIN);
    lv_obj_set_style_radius(rect, 0, LV_PART_MAIN);      // 0 = sharp corners
    lv_obj_set_style_pad_all(rect, 0, LV_PART_MAIN);
    lv_obj_set_style_outline_opa(rect, LV_OPA_TRANSP, LV_PART_MAIN); // no focus outline
    lv_obj_set_style_shadow_opa(rect, LV_OPA_TRANSP, LV_PART_MAIN);  // no shadow
    lv_obj_move_foreground(rect);
    lv_obj_add_flag(rect, LV_OBJ_FLAG_HIDDEN);

    return rect;
}

void cropFullFrameToRoi(lv_obj_t *parent, uint8_t *fullFb, uint8_t *roiFb) {
    Gfx::GfxBuffer src{};
    Gfx::GfxBuffer dst{};

    uint32_t x = (FULL_FRAME_WIDTH - ROI_FRAME_WIDTH) / 2;
    uint32_t y = (FULL_FRAME_HEIGHT - ROI_FRAME_HEIGHT) / 2;

    uint32_t fullFbStride = FULL_FRAME_WIDTH * LV_COLOR_FORMAT_GET_SIZE(FULL_FRAME_COLOR_FORMAT);
    uint32_t fullFbOffset = (y * fullFbStride) + x;
    uint32_t fullFbSize = ROI_FRAME_HEIGHT * fullFbStride;

    src.buf = fullFb + fullFbOffset;
    src.width = ROI_FRAME_WIDTH;
    src.height = ROI_FRAME_HEIGHT;
    src.stride = fullFbStride;
    src.cf = FULL_FRAME_COLOR_FORMAT;
    src.size = fullFbSize - fullFbOffset;

    uint32_t roiFbStride = ROI_FRAME_WIDTH * LV_COLOR_FORMAT_GET_SIZE(LV_COLOR_FORMAT_L8);

    dst.buf = roiFb;
    dst.width = ROI_FRAME_WIDTH;
    dst.height = ROI_FRAME_HEIGHT;
    dst.stride = roiFbStride;
    dst.cf = LV_COLOR_FORMAT_L8;
    dst.size = ROI_FRAME_HEIGHT * roiFbStride;

    Gfx::fit(parent, src, dst);
    lv_task_handler();
}

void fitRoiFrameToThumbnail(lv_obj_t *parent, uint8_t *roiFb, uint8_t *tFb) {
    Gfx::GfxBuffer src{};
    Gfx::GfxBuffer dst{};

    uint32_t roiFbStride = ROI_FRAME_WIDTH * LV_COLOR_FORMAT_GET_SIZE(LV_COLOR_FORMAT_L8);

    src.buf = roiFb;
    src.width = ROI_FRAME_WIDTH;
    src.height = ROI_FRAME_HEIGHT;
    src.stride = roiFbStride;
    src.cf = LV_COLOR_FORMAT_L8;
    src.size = ROI_FRAME_HEIGHT * roiFbStride;

    uint32_t tnFbStride = THUMBNAIL_FRAME_WIDTH * LV_COLOR_FORMAT_GET_SIZE(LV_COLOR_FORMAT_L8);

    dst.buf = tFb;
    dst.width = THUMBNAIL_FRAME_WIDTH;
    dst.height = THUMBNAIL_FRAME_HEIGHT;
    dst.stride = tnFbStride;
    dst.cf = LV_COLOR_FORMAT_L8;
    dst.size = THUMBNAIL_FRAME_HEIGHT * tnFbStride;

    Gfx::fit(parent, src, dst);
    lv_task_handler();
}
```

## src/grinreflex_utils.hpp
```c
#pragma once

#include <lvgl.h>

lv_obj_t *allocLvROIRect(lv_obj_t *parent, uint32_t borderWidth);

void cropFullFrameToRoi(lv_obj_t *parent, uint8_t *fullFb, uint8_t *roiFb);
void fitRoiFrameToThumbnail(lv_obj_t *parent, uint8_t *roiFb, uint8_t *tFb);
```

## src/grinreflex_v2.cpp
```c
#include <iostream>
#include <vector>

#if defined(CONFIG_OPENCV_LIB)
#include "opencv2/opencv.hpp"
#include "opencv_utils.hpp"
#include "cascades.h"
#endif 

#include <lvgl.h>
#include <lvgl_input_device.h>
#include <stdio.h>
#include <string.h>
#include <zephyr/device.h>
#include <zephyr/devicetree.h>
#include <zephyr/drivers/display.h>
#include <zephyr/drivers/gpio.h>
#include <zephyr/kernel.h>

#include <stdio.h>

#define LOG_LEVEL CONFIG_LOG_DEFAULT_LEVEL
#include <zephyr/logging/log.h>
LOG_MODULE_REGISTER(grinreflex_app);

#include "video.hpp"
#include "gfx_utils.hpp"

#include <app/drivers/jpeg.h>

#include "grinreflex_config.hpp"
#include "grinreflex_utils.hpp"
#include "grinreflex.h"

static const struct device *video_dev = DEVICE_DT_GET(DT_CHOSEN(zephyr_camera));
static const struct device *display_dev = DEVICE_DT_GET(DT_CHOSEN(zephyr_display));
const struct device *jpeg_dev = DEVICE_DT_GET(DT_CHOSEN(zephyr_jpeg));

static uint8_t fullFrameBuffer[FULL_FRAME_WIDTH * FULL_FRAME_HEIGHT * LV_COLOR_FORMAT_GET_SIZE(FULL_FRAME_COLOR_FORMAT)];
static uint8_t roiFrameBuffer[ROI_FRAME_WIDTH * ROI_FRAME_HEIGHT * LV_COLOR_FORMAT_GET_SIZE(LV_COLOR_FORMAT_L8)];
static uint8_t thumbnailFrameBuffer[THUMBNAIL_FRAME_WIDTH * THUMBNAIL_FRAME_HEIGHT * LV_COLOR_FORMAT_GET_SIZE(LV_COLOR_FORMAT_L8)];

static lv_obj_t *screen_canvas;
static lv_obj_t *dummy_canvas;
static lv_obj_t *screen;

#if defined(CONFIG_OPENCV_LIB)
static lv_obj_t *ROIRectFace;
static lv_obj_t *ROIRectSmile;
static cv::CascadeClassifier faceCascade;
static cv::CascadeClassifier smileCascade;
#endif /* defined(CONFIG_OPENCV_LIB) */

int init()
{
	if (!device_is_ready(display_dev)) {
		LOG_ERR("Display device not ready, aborting test");
		return -ENODEV;
	}

    if (!device_is_ready(video_dev)) {
		LOG_ERR("Video device not ready, aborting test");
		return -ENODEV;
	}

    if (!device_is_ready(jpeg_dev)) {
        printf("%s JPEG device not ready", jpeg_dev->name);
        return -ENODEV;
    }

#if defined(CONFIG_OPENCV_LIB)

    cv::setNumThreads(1);
    cv::setUseOptimized(false);


    if (false == loadCascade(faceCascade, cascade_face_data(), cascade_face_len())) {
        return -3;
    }

    if (false == loadCascade(smileCascade, cascade_smile_data(), cascade_smile_len())) {
        return -3;
    }

#endif /* defined(CONFIG_OPENCV_LIB) */

    Video::setup();

    dummy_canvas = lv_canvas_create(NULL);
    screen_canvas = lv_canvas_create(lv_screen_active());
    lv_canvas_fill_bg(screen_canvas, lv_color_hex3(0xccc), LV_OPA_COVER);
    lv_obj_center(screen_canvas);

    display_blanking_off(display_dev);

    screen = lv_img_create(lv_scr_act());

#if defined(CONFIG_OPENCV_LIB)
    ROIRectFace = allocLvROIRect(lv_scr_act(), 4);
    ROIRectSmile = allocLvROIRect(lv_scr_act(), 2);
#endif

    return 0;
}

int loop()
{

    struct video_buffer vbuf{};
    struct video_buffer *vbuf_ptr = &vbuf;
    struct jpeg_out_prop jpeg_prop;

    vbuf_ptr->type = VIDEO_BUF_TYPE_OUTPUT;
    
    int err = video_dequeue(video_dev, &vbuf_ptr, K_FOREVER);
    if (err) {
        LOG_ERR("Unable to dequeue video buf");
        return 0;
    }

    //jpeg_hw_decode(jpeg_dev, (uint8_t *)vbuf_ptr->buffer, vbuf_ptr->bytesused, jpeg_frame_buffer);

    jpeg_hw_poll(jpeg_dev, 0, &jpeg_prop);

    //printf("JPEG done w = %d, h = %d, color = %d chroma = %d\n", jpeg_prop.width,
    //        jpeg_prop.height, jpeg_prop.color_space, jpeg_prop.chroma);

    jpeg_color_convert_helper(jpeg_dev, &jpeg_prop, vbuf_ptr->buffer, fullFrameBuffer);

#if !defined(CONFIG_OPENCV_LIB)

    cropFullFrameToRoi(dummy_canvas, fullFrameBuffer, roiFrameBuffer);
    fitRoiFrameToThumbnail(screen_canvas, roiFrameBuffer, thumbnailFrameBuffer);

    err = video_enqueue(video_dev, vbuf_ptr);
    if (err) {
        LOG_ERR("Unable to requeue video buf");
        return 0;
    }
#else /* !defined(CONFIG_OPENCV_LIB) */

    cropFullFrameToRoi(dummy_canvas, fullFrameBuffer, roiFrameBuffer);
    fitRoiFrameToThumbnail(screen_canvas, roiFrameBuffer, thumbnailFrameBuffer);

    err = video_enqueue(video_dev, vbuf_ptr);
    if (err) {
        LOG_ERR("Unable to requeue video buf");
        return 0;
    }

    cv::Mat matGraySmall(THUMBNAIL_FRAME_HEIGHT, THUMBNAIL_FRAME_WIDTH, CV_8UC1, thumbnailFrameBuffer);
    cv::Mat matGrayFull(ROI_FRAME_HEIGHT, ROI_FRAME_WIDTH, CV_8UC1, roiFrameBuffer);

    cv::Rect faceROIMax{};
    faceROIMax.width = 60;
    faceROIMax.height = 60;

    std::vector<cv::Rect> faces;
    std::vector<cv::Rect> smiles;

    std::vector<cv::Rect> objects = detectFaceAndSmile(
        faceCascade,
        smileCascade,
        matGraySmall,
        matGrayFull,
        faceROIMax,
        faces,
        smiles
    );

    if (faces.size()) {
        lv_obj_remove_flag(ROIRectFace, LV_OBJ_FLAG_HIDDEN);

        auto object = faces[0];
        lv_obj_align_to(ROIRectFace, screen_canvas, LV_ALIGN_TOP_LEFT, object.x, object.y);
        lv_obj_set_size(ROIRectFace, object.width, object.height);

    } else {
        lv_obj_add_flag(ROIRectFace, LV_OBJ_FLAG_HIDDEN);
    }

    if (smiles.size()) {
        auto object = smiles[0];
        lv_obj_align_to(ROIRectSmile, screen_canvas, LV_ALIGN_TOP_LEFT, object.x, object.y);
        lv_obj_set_size(ROIRectSmile, object.width, object.height);

        lv_obj_remove_flag(ROIRectSmile, LV_OBJ_FLAG_HIDDEN);
    } else {
        lv_obj_add_flag(ROIRectSmile, LV_OBJ_FLAG_HIDDEN);
    }

#endif /* !defined(CONFIG_OPENCV_LIB) */
    return 0;
}
```

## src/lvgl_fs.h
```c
#ifndef _LVGL_FS_H_
#define _LVGL_FS_H_

void lvgl_fs_sample ();

uint8_t *lvgl_fs_load_raw (const char *path, uint8_t *buffer, size_t size);

#endif /*_LVGL_FS_H_*/
```

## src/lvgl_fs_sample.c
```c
//#include <lv_fs.h>

#include <stdint.h>
#include <stdbool.h>
#include <string.h>
#include <stdlib.h>

#include <zephyr/fs/fs.h>
#include <zephyr/logging/log.h>
LOG_MODULE_REGISTER(lvgl_fs_sample_config);

#include <lvgl.h>

#define MOUNT_POINT "/NAND:"
#define MAX_PATH 128

// File structure wrapper
typedef struct {
    struct fs_file_t file;
} lvgl_fs_file_t;

// Directory structure wrapper
typedef struct {
    struct fs_dir_t dir;
    struct fs_dirent entry;
} lvgl_fs_dir_t;

static bool _ready_cb(struct _lv_fs_drv_t *drv);
static void *_open_cb(lv_fs_drv_t *drv, const char *path, lv_fs_mode_t mode);
static lv_fs_res_t _close_cb(lv_fs_drv_t *drv, void *file_p);
static lv_fs_res_t _read_cb(lv_fs_drv_t *drv, void *file_p, void *buf, uint32_t btr, uint32_t *br);
static lv_fs_res_t _write_cb(lv_fs_drv_t *drv, void *file_p, const void *buf, uint32_t btw, uint32_t *bw);
static lv_fs_res_t _seek_cb(lv_fs_drv_t *drv, void *file_p, uint32_t pos, lv_fs_whence_t whence);
static lv_fs_res_t _tell_cb(lv_fs_drv_t *drv, void *file_p, uint32_t *pos_p);
static void *_dir_open_cb(lv_fs_drv_t *drv, const char *path);
static lv_fs_res_t _dir_read_cb(lv_fs_drv_t *drv, void *rdir_p, char *fn, uint32_t fn_len);
static lv_fs_res_t _dir_close_cb(lv_fs_drv_t *drv, void *rdir_p);

void lvgl_fs_sample ()
{
    static lv_fs_drv_t drv;                   /*Needs to be static or global*/
    lv_fs_drv_init(&drv);                     /*Basic initialization*/

    drv.letter = 'S';                         /*An uppercase letter to identify the drive */
    drv.ready_cb = _ready_cb;                 /*Callback to tell if the drive is ready to use */
    drv.open_cb = _open_cb;                   /*Callback to open a file */
    drv.close_cb = _close_cb;                 /*Callback to close a file */
    drv.read_cb = _read_cb;                   /*Callback to read a file */
    drv.write_cb = _write_cb;                 /*Callback to write a file */
    drv.seek_cb = _seek_cb;                   /*Callback to seek in a file (Move cursor) */
    drv.tell_cb = _tell_cb;                   /*Callback to tell the cursor position  */

    drv.dir_open_cb = _dir_open_cb;           /*Callback to open directory to read its content */
    drv.dir_read_cb = _dir_read_cb;           /*Callback to read a directory's content */
    drv.dir_close_cb = _dir_close_cb;         /*Callback to close a directory */

    drv.user_data = NULL;             /*Any custom data if required*/

    lv_fs_drv_register(&drv);                 /*Finally register the drive*/
}


static bool _ready_cb(struct _lv_fs_drv_t *drv)
{
    return true;  // For most cases, if mounted properly
}

static void *_open_cb(lv_fs_drv_t *drv, const char *path, lv_fs_mode_t mode)
{
    lvgl_fs_file_t *f = (lvgl_fs_file_t *)malloc(sizeof(lvgl_fs_file_t));

    if (!f) return NULL;

    fs_file_t_init(&f->file);

    char full_path[MAX_PATH];
    snprintf(full_path, sizeof(full_path), MOUNT_POINT"%s", path);

    int flags = 0;
    if (mode == LV_FS_MODE_WR)
        flags = FS_O_WRITE | FS_O_CREATE;
    else if (mode == LV_FS_MODE_RD)
        flags = FS_O_READ;
    else if (mode == (LV_FS_MODE_WR | LV_FS_MODE_RD))
        flags = FS_O_READ | FS_O_WRITE | FS_O_CREATE;

    int ret = fs_open(&f->file, full_path, flags);
    if (ret < 0) {
        free(f);
        return NULL;
    }

    return f;
}

static lv_fs_res_t _close_cb(lv_fs_drv_t *drv, void *file_p)
{
    lvgl_fs_file_t *f = file_p;

    fs_close(&f->file);
    free(f);
    return LV_FS_RES_OK;
}

static lv_fs_res_t _read_cb(lv_fs_drv_t *drv, void *file_p, void *buf, uint32_t btr, uint32_t *br)
{
    lvgl_fs_file_t *f = file_p;

    ssize_t r = fs_read(&f->file, buf, btr);
    if (r < 0) return LV_FS_RES_UNKNOWN;
    *br = r;
    return LV_FS_RES_OK;
}

static lv_fs_res_t _write_cb(lv_fs_drv_t *drv, void *file_p, const void *buf, uint32_t btw, uint32_t *bw)
{
    lvgl_fs_file_t *f = file_p;
    ssize_t w = fs_write(&f->file, buf, btw);
    if (w < 0) return LV_FS_RES_UNKNOWN;
    *bw = w;
    return LV_FS_RES_OK;
}

static lv_fs_res_t _seek_cb(lv_fs_drv_t *drv, void *file_p, uint32_t pos, lv_fs_whence_t whence)
{
    lvgl_fs_file_t *f = file_p;

    int z_whence;
    switch (whence) {
        case LV_FS_SEEK_SET: z_whence = FS_SEEK_SET; break;
        case LV_FS_SEEK_CUR: z_whence = FS_SEEK_CUR; break;
        case LV_FS_SEEK_END: z_whence = FS_SEEK_END; break;
        default: return LV_FS_RES_INV_PARAM;
    }

    int ret = fs_seek(&f->file, pos, z_whence);
    return (ret < 0) ? LV_FS_RES_UNKNOWN : LV_FS_RES_OK;
}

static lv_fs_res_t _tell_cb(lv_fs_drv_t *drv, void *file_p, uint32_t *pos_p)
{
    lvgl_fs_file_t *f = file_p;

    off_t pos = fs_tell(&f->file);
    if (pos < 0) return LV_FS_RES_UNKNOWN;
    *pos_p = pos;
    return LV_FS_RES_OK;
}

static void *_dir_open_cb(lv_fs_drv_t *drv, const char *path)
{
    lvgl_fs_dir_t *d = (lvgl_fs_dir_t *)malloc(sizeof(lvgl_fs_dir_t));

    if (!d) return NULL;

    fs_dir_t_init(&d->dir);

    char full_path[128];
    snprintf(full_path, sizeof(full_path), MOUNT_POINT"/%s", path);

    if (fs_opendir(&d->dir, full_path) < 0) {
        free(d);
        return NULL;
    }

    return d;
}

static lv_fs_res_t _dir_read_cb(lv_fs_drv_t *drv, void *rdir_p, char *fn, uint32_t fn_len)
{
    lvgl_fs_dir_t *d = rdir_p;
    int ret = fs_readdir(&d->dir, &d->entry);
    if (ret < 0 || d->entry.name[0] == 0) {
        fn[0] = '\0'; // No more files
        return LV_FS_RES_OK;
    }

    strncpy(fn, d->entry.name, LV_FS_MAX_FN_LENGTH);
    return LV_FS_RES_OK;
}

static lv_fs_res_t _dir_close_cb(lv_fs_drv_t *drv, void *rdir_p)
{
    lvgl_fs_dir_t *d = rdir_p;
    fs_closedir(&d->dir);
    free(d);
    return LV_FS_RES_OK;
}

uint8_t *lvgl_fs_load_raw (const char *path, uint8_t *buffer, size_t size)
{
    struct fs_file_t file;
    fs_file_t_init(&file);

    int ret = fs_open(&file, path, FS_O_READ);
    if (ret < 0) {
        LOG_ERR("Failed to open %s: %d\n", path, ret);
        return NULL;
    }

    ssize_t read_bytes = fs_read(&file, buffer, size);
    fs_close(&file);

    if (read_bytes != size) {
        LOG_ERR("Read %d bytes, expected %d\n", (int)read_bytes, (int)size);
        return NULL;
    }

    return buffer;
}
```
